# ATtiny102 register map
Vendor: Atmel; File version: 1.0
CPU: other r0p0, little endian, no MPU, no FPU, 4 interrupt priority bits
Registers are 8-bit, read-write, reset 0x0 unless marked. A register's access mark holds for its fields unless they carry their own. Offsets are from the block's base; [hi:lo] are bit positions; {n}, {i} and the like mark numbered series.

## EXINT — External Interrupts
Base 0x0080000F
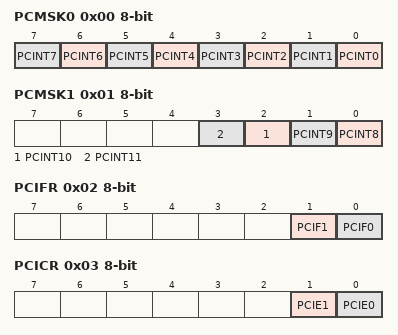
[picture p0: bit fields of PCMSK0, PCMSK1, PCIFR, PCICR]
0x00 PCMSK0 — Pin Change Mask Register 0
  [n] PCINT{n} (n=0..7) — Pin Change Enable Mask 0 Bit {n}
0x01 PCMSK1 — Pin Change Mask Register 1
  [n-8] PCINT{n} (n=8..11) — Pin Change Enable Mask 1 Bit {n-8}
0x02 PCIFR — Pin Change Interrupt Flag Register
  [1] PCIF1 — Pin Change Interrupt Flag 1
  [0] PCIF0 — Pin Change Interrupt Flag 0
0x03 PCICR — Pin Change Interrupt Control Register
  [1] PCIE1 — Pin Change Interrupt Enable 1
  [0] PCIE0 — Pin Change Interrupt Enable 0
0x04 EIMSK — External Interrupt Mask register
  [0] INT0 — External Interrupt Request 0 Enable
0x05 EIFR — External Interrupt Flag register
  [0] INTF0 — External Interrupt Flag 0
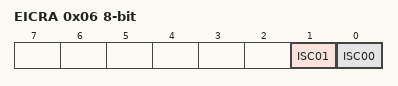
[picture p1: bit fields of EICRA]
0x06 EICRA — External Interrupt Control Register A
  [1] ISC01 — Interrupt Sense Control 0 Bit 1
  [0] ISC00 — Interrupt Sense Control 0 Bit 0

## FUSE — Fuses
Base 0x00800000
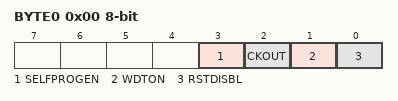
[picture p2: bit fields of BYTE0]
0x00 BYTE0
  [3] SELFPROGEN — Self programming enable
  [2] CKOUT — Output external clock
  [1] WDTON — Watch dog timer always on
  [0] RSTDISBL — Disable external reset

## LOCKBIT — Lockbits
Base 0x00800000
0x00 LOCKBIT
  [1:0] LB — Memory Lock
    0=PROG_VER_DISABLED (Further programming and verification disabled); 2=PROG_DISABLED (Further programming disabled); 3=NO_LOCK (No memory lock features enabled)

## PORTA — I/O Port
Base 0x00800000
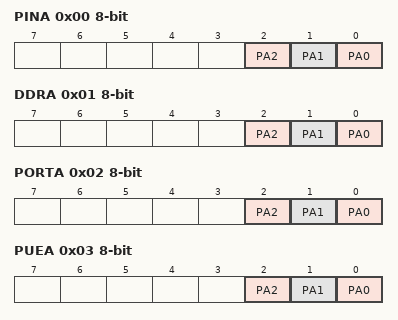
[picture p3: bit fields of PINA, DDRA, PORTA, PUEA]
0x00 PINA — Input Pins, Port A
  [2] PA2 — Pin A2
  [1] PA1 — Pin A1
  [0] PA0 — Pin A0
0x01 DDRA — Data Direction Register, Port A
  [2] PA2 — Pin A2
  [1] PA1 — Pin A1
  [0] PA0 — Pin A0
0x02 PORTA — Port A Data register
  [2] PA2 — Pin A2
  [1] PA1 — Pin A1
  [0] PA0 — Pin A0
0x03 PUEA — Pull-up Enable Control Register for PORTA
  [2] PA2 — Pin A2
  [1] PA1 — Pin A1
  [0] PA0 — Pin A0
0x16 PORTCR — Port Control Register
  [0] BBMA — Break-Before-Make Mode Enable for PORTA

## PORTB — I/O Port
Base 0x00800004
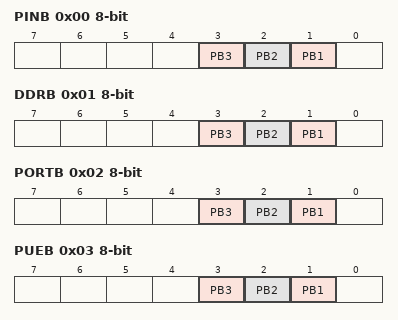
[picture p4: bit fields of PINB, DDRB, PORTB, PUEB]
0x00 PINB — Input Pins, Port B
  [3] PB3 — Pin B3
  [2] PB2 — Pin B2
  [1] PB1 — Pin B1
0x01 DDRB — Data Direction Register, Port B
  [3] PB3 — Pin B3
  [2] PB2 — Pin B2
  [1] PB1 — Pin B1
0x02 PORTB — Port B Data register
  [3] PB3 — Pin B3
  [2] PB2 — Pin B2
  [1] PB1 — Pin B1
0x03 PUEB — Pull-up Enable Control Register for PORTB
  [3] PB3 — Pin B3
  [2] PB2 — Pin B2
  [1] PB1 — Pin B1
0x12 PORTCR — Port Control Register
  [1] BBMB — Break-Before-Make Mode Enable for PORTB

## TC0 — Timer/Counter, 16-bit
Base 0x00800022
0x00 ICR0 16-bit (reset mask 0xFF) — Input Capture Register Bytes
0x02 OCR0B 16-bit (reset mask 0xFF) — Timer/Counter0 Output Compare Register B
0x04 OCR0A 16-bit (reset mask 0xFF) — Timer/Counter 0 Output Compare Register A
0x06 TCNT0 16-bit (reset mask 0xFF) — Timer/Counter0
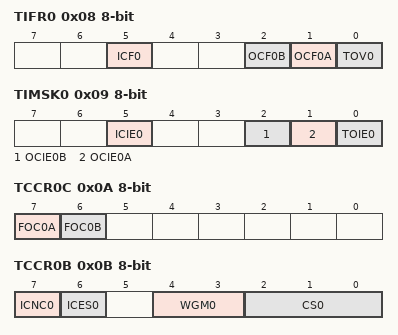
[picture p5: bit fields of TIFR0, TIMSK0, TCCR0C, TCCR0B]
0x08 TIFR0 — Overflow Interrupt Enable
  [5] ICF0 — Input Capture Flag
  [2] OCF0B — Timer Output Compare Flag 0B
  [1] OCF0A — Timer Output Compare Flag 0A
  [0] TOV0 — Timer Overflow Flag
0x09 TIMSK0 — Timer Interrupt Mask Register 0
  [5] ICIE0 — Input Capture Interrupt Enable
  [2] OCIE0B — Output Compare B Match Interrupt Enable
  [1] OCIE0A — Output Compare A Match Interrupt Enable
  [0] TOIE0 — Overflow Interrupt Enable
0x0A TCCR0C — Timer/Counter 0 Control Register C
  [7] FOC0A — Force Output Compare for Channel A
  [6] FOC0B — Force Output Compare for Channel B
0x0B TCCR0B — Timer/Counter 0 Control Register B
  [7] ICNC0 — Input Capture Noise Canceler
  [6] ICES0 — Input Capture Edge Select
  [4:3] WGM0 — Waveform Generation Mode
  [2:0] CS0 — Clock Select
    0=NO_CLOCK_SOURCE_STOPPED; 1=RUNNING_NO_PRESCALING; 2=RUNNING_CLK_8; 3=RUNNING_CLK_64; 4=RUNNING_CLK_256; 5=RUNNING_CLK_1024; 6=RUNNING_EXTCLK_TN_FALLING_EDGE; 7=RUNNING_EXTCLK_TN_RISING_EDGE
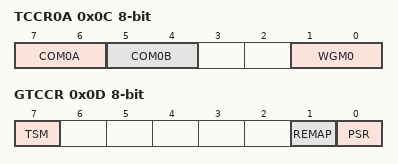
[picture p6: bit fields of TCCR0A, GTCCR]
0x0C TCCR0A — Timer/Counter 0 Control Register A
  [7:6] COM0A — Compare Output Mode for Channel A bits
  [5:4] COM0B — Compare Output Mode for Channel B bits
  [1:0] WGM0 — Waveform Generation Mode
0x0D GTCCR — General Timer/Counter Control Register
  [7] TSM — Timer Synchronization Mode
  [1] REMAP — Remap Bit for 14 pin part only
  [0] PSR — Prescaler Reset

## USART
Base 0x00800008
0x00 UDR — USART I/O Data Register
0x01 UBRR 16-bit (reset mask 0xFF) — USART Baud Rate Register Bytes
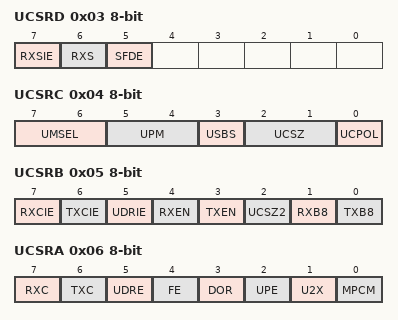
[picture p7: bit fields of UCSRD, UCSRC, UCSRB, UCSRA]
0x03 UCSRD — USART Control and Status Register D
  [7] RXSIE — USART RX Start Interrupt Enable
  [6] RXS — USART RX Start Flag
  [5] SFDE — Start frame detection enable
0x04 UCSRC — USART Control and Status Register C
  [7:6] UMSEL — USART Mode Select
    0=ASYNCHRONOUS_OPERATION; 1=SYNCHRONOUS_OPERATION
  [5:4] UPM — Parity Mode Bits
    0=DISABLED; 2=ENABLED_EVEN_PARITY; 3=ENABLED_ODD_PARITY
  [3] USBS — Stop Bit Select
    0=1_BIT; 1=2_BIT
  [2:1] UCSZ — Character Size
  [0] UCPOL — Clock Polarity
0x05 UCSRB — USART Control and Status Register B
  [7] RXCIE — RX Complete Interrupt Enable
  [6] TXCIE — TX Complete Interrupt Enable
  [5] UDRIE — USART Data register Empty Interrupt Enable
  [4] RXEN — Receiver Enable
  [3] TXEN — Transmitter Enable
  [2] UCSZ2 — Character Size
  [1] RXB8 — Receive Data Bit 8
  [0] TXB8 — Transmit Data Bit 8
0x06 UCSRA — USART Control and Status Register A
  [7] RXC ro — USART Receive Complete
  [6] TXC — USART Transmit Complete
  [5] UDRE ro — USART Data Register Empty
  [4] FE ro — Framing Error
  [3] DOR ro — Data Overrun
  [2] UPE ro — Parity Error
  [1] U2X — Double the USART transmission speed
  [0] MPCM — Multi-processor Communication Mode

## WDT — Watchdog Timer
Base 0x00800031
0x00 WDTCSR — Watchdog Timer Control and Status Register
  [7] WDIF — Watchdog Timer Interrupt Flag
  [6] WDIE — Watchdog Timer Interrupt Enable
  [3] WDE — Watch Dog Enable
  [5:0] WDP — Watchdog Timer Prescaler Bits
    0=OSCILLATOR_CYCLES_2K; 1=OSCILLATOR_CYCLES_4K; 2=OSCILLATOR_CYCLES_8K; 3=OSCILLATOR_CYCLES_16K; 4=OSCILLATOR_CYCLES_32K; 5=OSCILLATOR_CYCLES_64K; 6=OSCILLATOR_CYCLES_128K; 7=OSCILLATOR_CYCLES_256K
